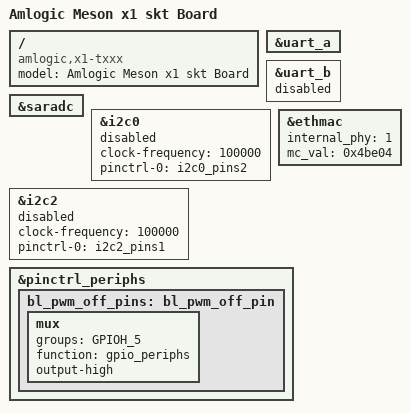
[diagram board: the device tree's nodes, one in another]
// SPDX-License-Identifier: (GPL-2.0+ OR MIT)
/*
 * Copyright (c) 2019 Amlogic, Inc. All rights reserved.
 */

/dts-v1/;

#include "amlogic/meson-x1-skt.dtsi"
#include "amlogic/meson-x1_skt-panel.dtsi"

/ {
	compatible =  "amlogic,x1-txxx", "amlogic,meson-x1";
	model = "Amlogic Meson x1 skt Board";
};

/* This UART is brought out to the DB9 connector */
&uart_a {
	status = "okay";
};

&uart_b {
	status = "disabled";
};

&saradc {
	status = "okay";
};

/* demo for i2c user */
&i2c0 {
	status= "disabled";
	clock-frequency = <100000>;
	pinctrl-names = "default";
	pinctrl-0 = <&i2c0_pins2>;
};

&i2c2 {
	status= "disabled";
	clock-frequency = <100000>;
	pinctrl-names = "default";
	pinctrl-0 = <&i2c2_pins1>;
};

&ethmac {
	status = "okay";
	internal_phy = <1>;
	mc_val = <0x4be04>;
	/*mc_val = <0x1621>;*/
};

&pinctrl_periphs {
	bl_pwm_off_pins:bl_pwm_off_pin {
		mux {
			groups = "GPIOH_5";
			function = "gpio_periphs";
			output-high;
		};
	};
}; /* end of pinctrl_periphs */
